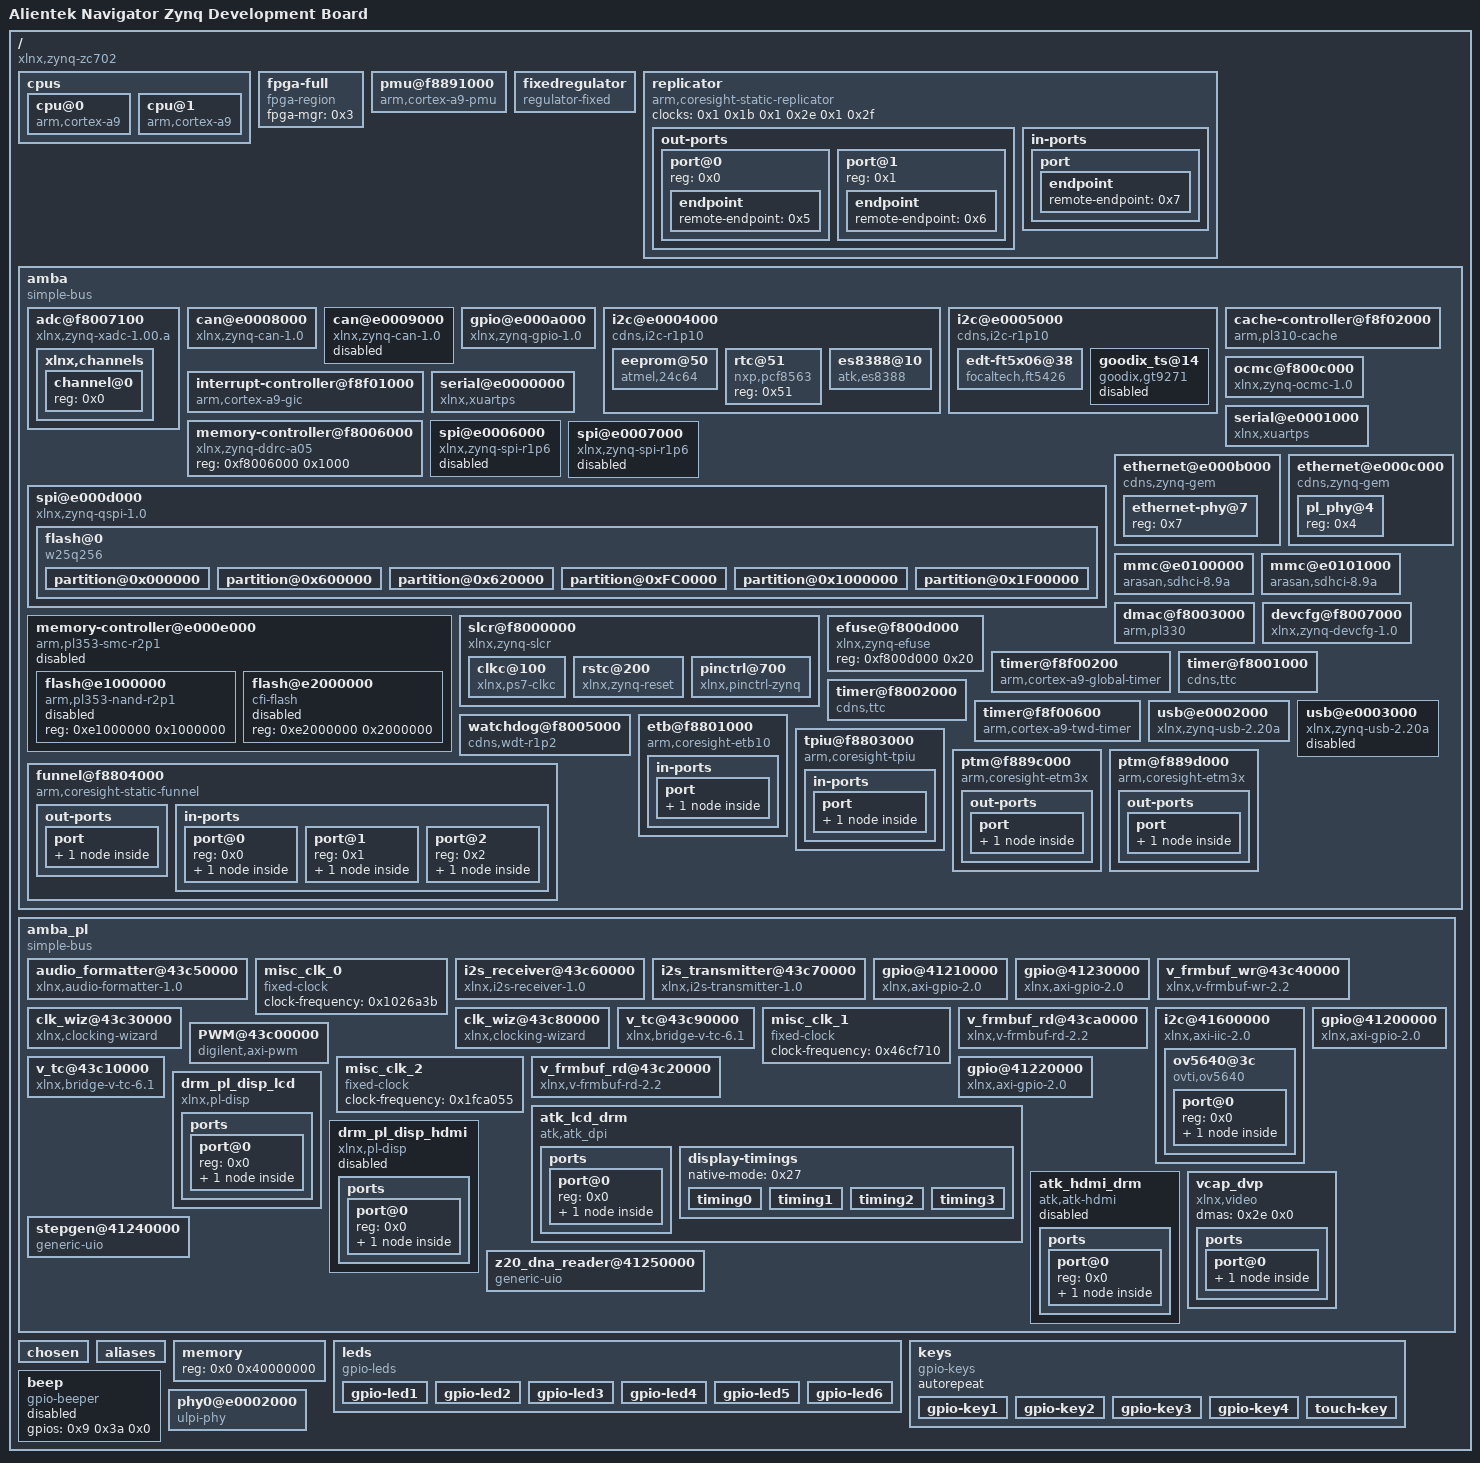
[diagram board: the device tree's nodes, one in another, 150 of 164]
/dts-v1/;

/ {
	#address-cells = <0x1>;
	#size-cells = <0x1>;
	compatible = "xlnx,zynq-zc702", "xlnx,zynq-7000";
	model = "Alientek Navigator Zynq Development Board";

	cpus {
		#address-cells = <0x1>;
		#size-cells = <0x0>;

		cpu@0 {
			compatible = "arm,cortex-a9";
			device_type = "cpu";
			reg = <0x0>;
			clocks = <0x1 0x3>;
			clock-latency = <0x3e8>;
			cpu0-supply = <0x2>;
			operating-points = <0xbb2ca 0xf4240 0x5d965 0xf4240>;
			phandle = <0x13>;
		};

		cpu@1 {
			compatible = "arm,cortex-a9";
			device_type = "cpu";
			reg = <0x1>;
			clocks = <0x1 0x3>;
			phandle = <0x15>;
		};
	};

	fpga-full {
		compatible = "fpga-region";
		fpga-mgr = <0x3>;
		#address-cells = <0x1>;
		#size-cells = <0x1>;
		ranges;
	};

	pmu@f8891000 {
		compatible = "arm,cortex-a9-pmu";
		interrupts = <0x0 0x5 0x4 0x0 0x6 0x4>;
		interrupt-parent = <0x4>;
		reg = <0xf8891000 0x1000 0xf8893000 0x1000>;
	};

	fixedregulator {
		compatible = "regulator-fixed";
		regulator-name = "VCCPINT";
		regulator-min-microvolt = <0xf4240>;
		regulator-max-microvolt = <0xf4240>;
		regulator-boot-on;
		regulator-always-on;
		phandle = <0x2>;
	};

	replicator {
		compatible = "arm,coresight-static-replicator";
		clocks = <0x1 0x1b 0x1 0x2e 0x1 0x2f>;
		clock-names = "apb_pclk", "dbg_trc", "dbg_apb";

		out-ports {
			#address-cells = <0x1>;
			#size-cells = <0x0>;

			port@0 {
				reg = <0x0>;

				endpoint {
					remote-endpoint = <0x5>;
					phandle = <0xf>;
				};
			};

			port@1 {
				reg = <0x1>;

				endpoint {
					remote-endpoint = <0x6>;
					phandle = <0xe>;
				};
			};
		};

		in-ports {

			port {

				endpoint {
					remote-endpoint = <0x7>;
					phandle = <0x10>;
				};
			};
		};
	};

	amba {
		u-boot,dm-pre-reloc;
		compatible = "simple-bus";
		#address-cells = <0x1>;
		#size-cells = <0x1>;
		interrupt-parent = <0x4>;
		ranges;

		adc@f8007100 {
			compatible = "xlnx,zynq-xadc-1.00.a";
			reg = <0xf8007100 0x20>;
			interrupts = <0x0 0x7 0x4>;
			interrupt-parent = <0x4>;
			clocks = <0x1 0xc>;
			status = "okay";

			xlnx,channels {
				#address-cells = <0x1>;
				#size-cells = <0x0>;

				channel@0 {
					reg = <0x0>;
				};
			};
		};

		can@e0008000 {
			compatible = "xlnx,zynq-can-1.0";
			status = "okay";
			clocks = <0x1 0x13 0x1 0x24>;
			clock-names = "can_clk", "pclk";
			reg = <0xe0008000 0x1000>;
			interrupts = <0x0 0x1c 0x4>;
			interrupt-parent = <0x4>;
			tx-fifo-depth = <0x40>;
			rx-fifo-depth = <0x40>;
		};

		can@e0009000 {
			compatible = "xlnx,zynq-can-1.0";
			status = "disabled";
			clocks = <0x1 0x14 0x1 0x25>;
			clock-names = "can_clk", "pclk";
			reg = <0xe0009000 0x1000>;
			interrupts = <0x0 0x33 0x4>;
			interrupt-parent = <0x4>;
			tx-fifo-depth = <0x40>;
			rx-fifo-depth = <0x40>;
		};

		gpio@e000a000 {
			compatible = "xlnx,zynq-gpio-1.0";
			#gpio-cells = <0x2>;
			clocks = <0x1 0x2a>;
			gpio-controller;
			interrupt-controller;
			#interrupt-cells = <0x2>;
			interrupt-parent = <0x4>;
			interrupts = <0x0 0x14 0x4>;
			reg = <0xe000a000 0x1000>;
			emio-gpio-width = <0xb>;
			gpio-mask-high = <0x0>;
			gpio-mask-low = <0x5600>;
			phandle = <0x9>;
		};

		i2c@e0004000 {
			compatible = "cdns,i2c-r1p10";
			status = "okay";
			clocks = <0x1 0x26>;
			interrupt-parent = <0x4>;
			interrupts = <0x0 0x19 0x4>;
			reg = <0xe0004000 0x1000>;
			#address-cells = <0x1>;
			#size-cells = <0x0>;
			clock-frequency = <0x186a0>;

			eeprom@50 {
				compatible = "atmel,24c64";
				reg = <0x50>;
				pagesize = <0x20>;
			};

			rtc@51 {
				compatible = "nxp,pcf8563";
				reg = <0x51>;
			};

			es8388@10 {
				compatible = "atk,es8388";
				reg = <0x10>;
				clock-names = "mclk";
				clocks = <0x8 0x1>;
				#sound-dai-cells = <0x0>;
				status = "okay";
				phandle = <0x1a>;
			};
		};

		i2c@e0005000 {
			compatible = "cdns,i2c-r1p10";
			status = "okay";
			clocks = <0x1 0x27>;
			interrupt-parent = <0x4>;
			interrupts = <0x0 0x30 0x4>;
			reg = <0xe0005000 0x1000>;
			#address-cells = <0x1>;
			#size-cells = <0x0>;
			clock-frequency = <0x186a0>;
			phandle = <0x2c>;

			edt-ft5x06@38 {
				compatible = "focaltech,ft5426", "edt,edt-ft5406";
				status = "okay";
				reg = <0x38>;
				interrupt-parent = <0x9>;
				interrupts = <0x3a 0x2>;
				reset-gpios = <0x9 0x3b 0x1>;
				touchscreen-size-x = <0x400>;
				touchscreen-size-y = <0x258>;
			};

			goodix_ts@14 {
				compatible = "goodix,gt9271", "goodix,gt911", "goodix,gt9xx";
				status = "disabled";
				reg = <0x14>;
				interrupt-parent = <0x9>;
				interrupts = <0x3a 0x0>;
				reset-gpio = <0x9 0x3b 0x1>;
				interrupt-gpio = <0x9 0x3a 0x0>;
				irq-gpios = <0x9 0x3a 0x0>;
				touchscreen-size-x = <0x400>;
				touchscreen-size-y = <0x258>;
			};
		};

		interrupt-controller@f8f01000 {
			compatible = "arm,cortex-a9-gic";
			#interrupt-cells = <0x3>;
			interrupt-controller;
			reg = <0xf8f01000 0x1000 0xf8f00100 0x100>;
			num_cpus = <0x2>;
			num_interrupts = <0x60>;
			phandle = <0x4>;
		};

		cache-controller@f8f02000 {
			compatible = "arm,pl310-cache";
			reg = <0xf8f02000 0x1000>;
			interrupts = <0x0 0x2 0x4>;
			arm,data-latency = <0x3 0x2 0x2>;
			arm,tag-latency = <0x2 0x2 0x2>;
			cache-unified;
			cache-level = <0x2>;
		};

		memory-controller@f8006000 {
			compatible = "xlnx,zynq-ddrc-a05";
			reg = <0xf8006000 0x1000>;
		};

		ocmc@f800c000 {
			compatible = "xlnx,zynq-ocmc-1.0";
			interrupt-parent = <0x4>;
			interrupts = <0x0 0x3 0x4>;
			reg = <0xf800c000 0x1000>;
		};

		serial@e0000000 {
			compatible = "xlnx,xuartps", "cdns,uart-r1p8";
			status = "okay";
			clocks = <0x1 0x17 0x1 0x28>;
			clock-names = "uart_clk", "pclk";
			reg = <0xe0000000 0x1000>;
			interrupts = <0x0 0x1b 0x4>;
			cts-override;
			device_type = "serial";
			port-number = <0x0>;
			u-boot,dm-pre-reloc;
		};

		serial@e0001000 {
			compatible = "xlnx,xuartps", "cdns,uart-r1p8";
			status = "okay";
			clocks = <0x1 0x18 0x1 0x29>;
			clock-names = "uart_clk", "pclk";
			reg = <0xe0001000 0x1000>;
			interrupts = <0x0 0x32 0x4>;
			cts-override;
			device_type = "serial";
			port-number = <0x1>;
		};

		spi@e0006000 {
			compatible = "xlnx,zynq-spi-r1p6";
			reg = <0xe0006000 0x1000>;
			status = "disabled";
			interrupt-parent = <0x4>;
			interrupts = <0x0 0x1a 0x4>;
			clocks = <0x1 0x19 0x1 0x22>;
			clock-names = "ref_clk", "pclk";
			#address-cells = <0x1>;
			#size-cells = <0x0>;
		};

		spi@e0007000 {
			compatible = "xlnx,zynq-spi-r1p6";
			reg = <0xe0007000 0x1000>;
			status = "disabled";
			interrupt-parent = <0x4>;
			interrupts = <0x0 0x31 0x4>;
			clocks = <0x1 0x1a 0x1 0x23>;
			clock-names = "ref_clk", "pclk";
			#address-cells = <0x1>;
			#size-cells = <0x0>;
		};

		spi@e000d000 {
			clock-names = "ref_clk", "pclk";
			clocks = <0x1 0xa 0x1 0x2b>;
			compatible = "xlnx,zynq-qspi-1.0";
			status = "okay";
			interrupt-parent = <0x4>;
			interrupts = <0x0 0x13 0x4>;
			reg = <0xe000d000 0x1000>;
			#address-cells = <0x1>;
			#size-cells = <0x0>;
			is-dual = <0x0>;
			num-cs = <0x1>;
			spi-rx-bus-width = <0x4>;
			spi-tx-bus-width = <0x4>;
			u-boot,dm-pre-reloc;

			flash@0 {
				compatible = "w25q256", "jedec,spi-nor";
				reg = <0x0>;
				spi-max-frequency = <0x2faf080>;
				#address-cells = <0x1>;
				#size-cells = <0x1>;

				partition@0x000000 {
					label = "boot";
					reg = <0x0 0x600000>;
				};

				partition@0x600000 {
					label = "bootenv";
					reg = <0x600000 0x20000>;
				};

				partition@0x620000 {
					label = "reserved";
					reg = <0x620000 0x9a0000>;
					read-only;
				};

				partition@0xFC0000 {
					label = "boot.scr";
					reg = <0xfc0000 0x40000>;
				};

				partition@0x1000000 {
					label = "image.ub";
					reg = <0x1000000 0xf00000>;
				};

				partition@0x1F00000 {
					label = "space";
					reg = <0x1f00000 0x100000>;
				};
			};
		};

		memory-controller@e000e000 {
			#address-cells = <0x1>;
			#size-cells = <0x1>;
			status = "disabled";
			clock-names = "memclk", "apb_pclk";
			clocks = <0x1 0xb 0x1 0x2c>;
			compatible = "arm,pl353-smc-r2p1", "arm,primecell";
			interrupt-parent = <0x4>;
			interrupts = <0x0 0x12 0x4>;
			ranges;
			reg = <0xe000e000 0x1000>;

			flash@e1000000 {
				status = "disabled";
				compatible = "arm,pl353-nand-r2p1";
				reg = <0xe1000000 0x1000000>;
				#address-cells = <0x1>;
				#size-cells = <0x1>;
			};

			flash@e2000000 {
				status = "disabled";
				compatible = "cfi-flash";
				reg = <0xe2000000 0x2000000>;
				#address-cells = <0x1>;
				#size-cells = <0x1>;
			};
		};

		ethernet@e000b000 {
			compatible = "cdns,zynq-gem", "cdns,gem";
			reg = <0xe000b000 0x1000>;
			status = "okay";
			interrupts = <0x0 0x16 0x4>;
			clocks = <0x1 0x1e 0x1 0x1e 0x1 0xd>;
			clock-names = "pclk", "hclk", "tx_clk";
			#address-cells = <0x1>;
			#size-cells = <0x0>;
			phy-mode = "rgmii-id";
			xlnx,ptp-enet-clock = <0x79dbbf3>;
			local-mac-address = [00 0a 35 00 8b 87];
			phy-handle = <0xa>;

			ethernet-phy@7 {
				reg = <0x7>;
				device_type = "ethernet-phy";
				phandle = <0xa>;
			};
		};

		ethernet@e000c000 {
			compatible = "cdns,zynq-gem", "cdns,gem";
			reg = <0xe000c000 0x1000>;
			status = "okay";
			interrupts = <0x0 0x2d 0x4>;
			clocks = <0x1 0x1f 0x1 0x1f 0x1 0xe>;
			clock-names = "pclk", "hclk", "tx_clk";
			#address-cells = <0x1>;
			#size-cells = <0x0>;
			phy-mode = "gmii";
			xlnx,ptp-enet-clock = <0x79dbbf3>;
			local-mac-address = [00 0a 35 00 11 55];
			phy-reset-gpio = <0x9 0x3f 0x1>;
			phy-reset-active-low;
			phy-handle = <0xb>;

			pl_phy@4 {
				reg = <0x4>;
				device_type = "ethernet-phy";
				phandle = <0xb>;
			};
		};

		mmc@e0100000 {
			compatible = "arasan,sdhci-8.9a";
			status = "okay";
			clock-names = "clk_xin", "clk_ahb";
			clocks = <0x1 0x15 0x1 0x20>;
			interrupt-parent = <0x4>;
			interrupts = <0x0 0x18 0x4>;
			reg = <0xe0100000 0x1000>;
			xlnx,has-cd = <0x1>;
			xlnx,has-power = <0x0>;
			xlnx,has-wp = <0x0>;
			u-boot,dm-pre-reloc;
		};

		mmc@e0101000 {
			compatible = "arasan,sdhci-8.9a";
			status = "okay";
			clock-names = "clk_xin", "clk_ahb";
			clocks = <0x1 0x16 0x1 0x21>;
			interrupt-parent = <0x4>;
			interrupts = <0x0 0x2f 0x4>;
			reg = <0xe0101000 0x1000>;
			xlnx,has-cd = <0x0>;
			xlnx,has-power = <0x0>;
			xlnx,has-wp = <0x0>;
		};

		slcr@f8000000 {
			u-boot,dm-pre-reloc;
			#address-cells = <0x1>;
			#size-cells = <0x1>;
			compatible = "xlnx,zynq-slcr", "syscon", "simple-mfd";
			reg = <0xf8000000 0x1000>;
			ranges;
			phandle = <0xc>;

			clkc@100 {
				u-boot,dm-pre-reloc;
				#clock-cells = <0x1>;
				compatible = "xlnx,ps7-clkc";
				fclk-enable = <0xf>;
				clock-output-names = "armpll", "ddrpll", "iopll", "cpu_6or4x", "cpu_3or2x", "cpu_2x", "cpu_1x", "ddr2x", "ddr3x", "dci", "lqspi", "smc", "pcap", "gem0", "gem1", "fclk0", "fclk1", "fclk2", "fclk3", "can0", "can1", "sdio0", "sdio1", "uart0", "uart1", "spi0", "spi1", "dma", "usb0_aper", "usb1_aper", "gem0_aper", "gem1_aper", "sdio0_aper", "sdio1_aper", "spi0_aper", "spi1_aper", "can0_aper", "can1_aper", "i2c0_aper", "i2c1_aper", "uart0_aper", "uart1_aper", "gpio_aper", "lqspi_aper", "smc_aper", "swdt", "dbg_trc", "dbg_apb";
				reg = <0x100 0x100>;
				ps-clk-frequency = <0x1fca055>;
				phandle = <0x1>;
			};

			rstc@200 {
				compatible = "xlnx,zynq-reset";
				reg = <0x200 0x48>;
				#reset-cells = <0x1>;
				syscon = <0xc>;
			};

			pinctrl@700 {
				compatible = "xlnx,pinctrl-zynq";
				reg = <0x700 0x200>;
				syscon = <0xc>;
			};
		};

		dmac@f8003000 {
			compatible = "arm,pl330", "arm,primecell";
			reg = <0xf8003000 0x1000>;
			interrupt-parent = <0x4>;
			interrupt-names = "abort", "dma0", "dma1", "dma2", "dma3", "dma4", "dma5", "dma6", "dma7";
			interrupts = <0x0 0xd 0x4 0x0 0xe 0x4 0x0 0xf 0x4 0x0 0x10 0x4 0x0 0x11 0x4 0x0 0x28 0x4 0x0 0x29 0x4 0x0 0x2a 0x4 0x0 0x2b 0x4>;
			#dma-cells = <0x1>;
			#dma-channels = <0x8>;
			#dma-requests = <0x4>;
			clocks = <0x1 0x1b>;
			clock-names = "apb_pclk";
		};

		devcfg@f8007000 {
			compatible = "xlnx,zynq-devcfg-1.0";
			interrupt-parent = <0x4>;
			interrupts = <0x0 0x8 0x4>;
			reg = <0xf8007000 0x100>;
			clocks = <0x1 0xc 0x1 0xf 0x1 0x10 0x1 0x11 0x1 0x12>;
			clock-names = "ref_clk", "fclk0", "fclk1", "fclk2", "fclk3";
			syscon = <0xc>;
			phandle = <0x3>;
		};

		efuse@f800d000 {
			compatible = "xlnx,zynq-efuse";
			reg = <0xf800d000 0x20>;
		};

		timer@f8f00200 {
			compatible = "arm,cortex-a9-global-timer";
			reg = <0xf8f00200 0x20>;
			interrupts = <0x1 0xb 0x301>;
			interrupt-parent = <0x4>;
			clocks = <0x1 0x4>;
		};

		timer@f8001000 {
			interrupt-parent = <0x4>;
			interrupts = <0x0 0xa 0x4 0x0 0xb 0x4 0x0 0xc 0x4>;
			compatible = "cdns,ttc";
			clocks = <0x1 0x6>;
			reg = <0xf8001000 0x1000>;
		};

		timer@f8002000 {
			interrupt-parent = <0x4>;
			interrupts = <0x0 0x25 0x4 0x0 0x26 0x4 0x0 0x27 0x4>;
			compatible = "cdns,ttc";
			clocks = <0x1 0x6>;
			reg = <0xf8002000 0x1000>;
		};

		timer@f8f00600 {
			interrupt-parent = <0x4>;
			interrupts = <0x1 0xd 0x301>;
			compatible = "arm,cortex-a9-twd-timer";
			reg = <0xf8f00600 0x20>;
			clocks = <0x1 0x4>;
		};

		usb@e0002000 {
			compatible = "xlnx,zynq-usb-2.20a", "chipidea,usb2";
			status = "okay";
			clocks = <0x1 0x1c>;
			interrupt-parent = <0x4>;
			interrupts = <0x0 0x15 0x4>;
			reg = <0xe0002000 0x1000>;
			phy_type = "ulpi";
			usb-reset = <0x9 0x9 0x0>;
			dr_mode = "otg";
			usb-phy = <0xd>;
		};

		usb@e0003000 {
			compatible = "xlnx,zynq-usb-2.20a", "chipidea,usb2";
			status = "disabled";
			clocks = <0x1 0x1d>;
			interrupt-parent = <0x4>;
			interrupts = <0x0 0x2c 0x4>;
			reg = <0xe0003000 0x1000>;
			phy_type = "ulpi";
		};

		watchdog@f8005000 {
			clocks = <0x1 0x2d>;
			compatible = "cdns,wdt-r1p2";
			interrupt-parent = <0x4>;
			interrupts = <0x0 0x9 0x1>;
			reg = <0xf8005000 0x1000>;
			timeout-sec = <0xa>;
			status = "okay";
			reset-on-timeout;
		};

		etb@f8801000 {
			compatible = "arm,coresight-etb10", "arm,primecell";
			reg = <0xf8801000 0x1000>;
			clocks = <0x1 0x1b 0x1 0x2e 0x1 0x2f>;
			clock-names = "apb_pclk", "dbg_trc", "dbg_apb";

			in-ports {

				port {

					endpoint {
						remote-endpoint = <0xe>;
						phandle = <0x6>;
					};
				};
			};
		};

		tpiu@f8803000 {
			compatible = "arm,coresight-tpiu", "arm,primecell";
			reg = <0xf8803000 0x1000>;
			clocks = <0x1 0x1b 0x1 0x2e 0x1 0x2f>;
			clock-names = "apb_pclk", "dbg_trc", "dbg_apb";

			in-ports {

				port {

					endpoint {
						remote-endpoint = <0xf>;
						phandle = <0x5>;
					};
				};
			};
		};

		funnel@f8804000 {
			compatible = "arm,coresight-static-funnel", "arm,primecell";
			reg = <0xf8804000 0x1000>;
			clocks = <0x1 0x1b 0x1 0x2e 0x1 0x2f>;
			clock-names = "apb_pclk", "dbg_trc", "dbg_apb";

			out-ports {

				port {

					endpoint {
						remote-endpoint = <0x10>;
						phandle = <0x7>;
					};
				};
			};

			in-ports {
				#address-cells = <0x1>;
				#size-cells = <0x0>;

				port@0 {
					reg = <0x0>;

					endpoint {
						remote-endpoint = <0x11>;
						phandle = <0x14>;
					};
				};

				port@1 {
					reg = <0x1>;

					endpoint {
						remote-endpoint = <0x12>;
						phandle = <0x16>;
					};
				};

				port@2 {
					reg = <0x2>;

					endpoint {
					};
				};
			};
		};

		ptm@f889c000 {
			compatible = "arm,coresight-etm3x", "arm,primecell";
			reg = <0xf889c000 0x1000>;
			clocks = <0x1 0x1b 0x1 0x2e 0x1 0x2f>;
			clock-names = "apb_pclk", "dbg_trc", "dbg_apb";
			cpu = <0x13>;

			out-ports {

				port {

					endpoint {
						remote-endpoint = <0x14>;
						phandle = <0x11>;
					};
				};
			};
		};

		ptm@f889d000 {
			compatible = "arm,coresight-etm3x", "arm,primecell";
			reg = <0xf889d000 0x1000>;
			clocks = <0x1 0x1b 0x1 0x2e 0x1 0x2f>;
			clock-names = "apb_pclk", "dbg_trc", "dbg_apb";
			cpu = <0x15>;

			out-ports {

				port {

					endpoint {
						remote-endpoint = <0x16>;
						phandle = <0x12>;
					};
				};
			};
		};
	};

	amba_pl {
		#address-cells = <0x1>;
		#size-cells = <0x1>;
		compatible = "simple-bus";
		ranges;

		audio_formatter@43c50000 {
			clock-names = "s_axi_lite_aclk", "m_axis_mm2s_aclk", "aud_mclk", "s_axis_s2mm_aclk";
			clocks = <0x1 0xf 0x1 0xf 0x17 0x1 0xf>;
			compatible = "xlnx,audio-formatter-1.0", "xlnx,audio-formatter-1.0";
			interrupt-names = "irq_mm2s", "irq_s2mm";
			interrupt-parent = <0x4>;
			interrupts = <0x0 0x24 0x4 0x0 0x21 0x4>;
			reg = <0x43c50000 0x10000>;
			xlnx,include-mm2s = <0x1>;
			xlnx,include-s2mm = <0x1>;
			xlnx,max-num-channels-mm2s = <0x2>;
			xlnx,max-num-channels-s2mm = <0x2>;
			xlnx,mm2s-addr-width = <0x20>;
			xlnx,mm2s-async-clock = <0x0>;
			xlnx,mm2s-dataformat = <0x3>;
			xlnx,packing-mode-mm2s = <0x0>;
			xlnx,packing-mode-s2mm = <0x0>;
			xlnx,rx = <0x18>;
			xlnx,s2mm-addr-width = <0x20>;
			xlnx,s2mm-async-clock = <0x0>;
			xlnx,s2mm-dataformat = <0x1>;
			xlnx,tx = <0x19>;
			audio-codec = <0x1a>;
			phandle = <0x1b>;
		};

		misc_clk_0 {
			#clock-cells = <0x0>;
			clock-frequency = <0x1026a3b>;
			compatible = "fixed-clock";
			phandle = <0x17>;
		};

		i2s_receiver@43c60000 {
			aud_mclk = <0x1026a3b>;
			clock-names = "s_axi_ctrl_aclk", "aud_mclk", "m_axis_aud_aclk";
			clocks = <0x1 0xf 0x17 0x1 0xf>;
			compatible = "xlnx,i2s-receiver-1.0", "xlnx,i2s-receiver-1.0";
			interrupt-names = "irq";
			interrupt-parent = <0x4>;
			interrupts = <0x0 0x23 0x4>;
			reg = <0x43c60000 0x10000>;
			xlnx,depth = <0x80>;
			xlnx,dwidth = <0x18>;
			xlnx,num-channels = <0x1>;
			xlnx,snd-pcm = <0x1b>;
			phandle = <0x18>;
		};

		i2s_transmitter@43c70000 {
			aud_mclk = <0x1026a3b>;
			clock-names = "s_axi_ctrl_aclk", "aud_mclk", "s_axis_aud_aclk";
			clocks = <0x1 0xf 0x17 0x1 0xf>;
			compatible = "xlnx,i2s-transmitter-1.0", "xlnx,i2s-transmitter-1.0";
			interrupt-names = "irq";
			interrupt-parent = <0x4>;
			interrupts = <0x0 0x22 0x4>;
			reg = <0x43c70000 0x10000>;
			xlnx,depth = <0x80>;
			xlnx,dwidth = <0x18>;
			xlnx,num-channels = <0x1>;
			xlnx,snd-pcm = <0x1b>;
			phandle = <0x19>;
		};

		gpio@41210000 {
			#gpio-cells = <0x3>;
			clock-names = "s_axi_aclk";
			clocks = <0x1 0xf>;
			compatible = "xlnx,axi-gpio-2.0", "xlnx,xps-gpio-1.00.a";
			gpio-controller;
			reg = <0x41210000 0x10000>;
			xlnx,all-inputs = <0x0>;
			xlnx,all-inputs-2 = <0x0>;
			xlnx,all-outputs = <0x1>;
			xlnx,all-outputs-2 = <0x0>;
			xlnx,dout-default = <0x0>;
			xlnx,dout-default-2 = <0x0>;
			xlnx,gpio-width = <0x2>;
			xlnx,gpio2-width = <0x20>;
			xlnx,interrupt-present = <0x0>;
			xlnx,is-dual = <0x0>;
			xlnx,tri-default = <0xffffffff>;
			xlnx,tri-default-2 = <0xffffffff>;
			phandle = <0x30>;
		};

		gpio@41230000 {
			#gpio-cells = <0x3>;
			clock-names = "s_axi_aclk";
			clocks = <0x1 0xf>;
			compatible = "xlnx,axi-gpio-2.0", "xlnx,xps-gpio-1.00.a";
			gpio-controller;
			reg = <0x41230000 0x10000>;
			xlnx,all-inputs = <0x0>;
			xlnx,all-inputs-2 = <0x0>;
			xlnx,all-outputs = <0x1>;
			xlnx,all-outputs-2 = <0x0>;
			xlnx,dout-default = <0x0>;
			xlnx,dout-default-2 = <0x0>;
			xlnx,gpio-width = <0x1>;
			xlnx,gpio2-width = <0x20>;
			xlnx,interrupt-present = <0x0>;
			xlnx,is-dual = <0x0>;
			xlnx,tri-default = <0xffffffff>;
			xlnx,tri-default-2 = <0xffffffff>;
			phandle = <0x1e>;
		};

		v_frmbuf_wr@43c40000 {
			#dma-cells = <0x1>;
			clock-names = "ap_clk";
			clocks = <0x1 0x10>;
			compatible = "xlnx,v-frmbuf-wr-2.2", "xlnx,axi-frmbuf-wr-v2.1";
			interrupt-names = "interrupt";
			interrupt-parent = <0x4>;
			interrupts = <0x0 0x1f 0x4>;
			reg = <0x43c40000 0x10000>;
			reset-gpios = <0x1c 0x1 0x0 0x1>;
			xlnx,dma-addr-width = <0x20>;
			xlnx,dma-align = <0x8>;
			xlnx,max-height = <0x438>;
			xlnx,max-width = <0x780>;
			xlnx,pixels-per-clock = <0x1>;
			xlnx,s-axi-ctrl-addr-width = <0x7>;
			xlnx,s-axi-ctrl-data-width = <0x20>;
			xlnx,vid-formats = "rgb888", "bgr888";
			xlnx,video-width = <0x8>;
			phandle = <0x2e>;
		};

		clk_wiz@43c30000 {
			#clock-cells = <0x1>;
			clock-names = "s_axi_aclk", "clk_in1";
			clock-output-names = "0x43c30000-lcd_pclk", "0x43c30000-mclk";
			clocks = <0x1 0xf 0x1 0xf>;
			compatible = "xlnx,clocking-wizard";
			reg = <0x43c30000 0x10000>;
			speed-grade = <0x2>;
			xlnx,nr-outputs = <0x2>;
			phandle = <0x8>;
		};

		clk_wiz@43c80000 {
			#clock-cells = <0x1>;
			clock-names = "s_axi_aclk", "clk_in1";
			clock-output-names = "0x43c80000-hdmi_pclk", "0x43c80000-hdmi_pclk_5x";
			clocks = <0x1 0xf 0x1 0xf>;
			compatible = "xlnx,clocking-wizard";
			reg = <0x43c80000 0x10000>;
			speed-grade = <0x2>;
			xlnx,nr-outputs = <0x2>;
			phandle = <0x2b>;
		};

		v_tc@43c90000 {
			clock-names = "clk", "s_axi_aclk";
			clocks = <0x1d 0x1 0xf>;
			compatible = "xlnx,bridge-v-tc-6.1";
			interrupt-names = "irq";
			interrupt-parent = <0x4>;
			interrupts = <0x0 0x35 0x4>;
			reg = <0x43c90000 0x10000>;
			xlnx,generator;
			xlnx,pixels-per-clock = <0x1>;
			phandle = <0x29>;
		};

		misc_clk_1 {
			#clock-cells = <0x0>;
			clock-frequency = <0x46cf710>;
			compatible = "fixed-clock";
			phandle = <0x1d>;
		};

		v_frmbuf_rd@43ca0000 {
			#dma-cells = <0x1>;
			clock-names = "ap_clk";
			clocks = <0x1d>;
			compatible = "xlnx,v-frmbuf-rd-2.2", "xlnx,axi-frmbuf-rd-v2.1";
			interrupt-names = "interrupt";
			interrupt-parent = <0x4>;
			interrupts = <0x0 0x34 0x4>;
			reg = <0x43ca0000 0x10000>;
			reset-gpios = <0x1c 0x2 0x0 0x1>;
			xlnx,dma-addr-width = <0x20>;
			xlnx,dma-align = <0x8>;
			xlnx,max-height = <0x438>;
			xlnx,max-width = <0x780>;
			xlnx,pixels-per-clock = <0x1>;
			xlnx,s-axi-ctrl-addr-width = <0x7>;
			xlnx,s-axi-ctrl-data-width = <0x20>;
			xlnx,vid-formats = "rgb888", "bgr888";
			xlnx,video-width = <0x8>;
			phandle = <0x28>;
		};

		i2c@41600000 {
			#address-cells = <0x1>;
			#size-cells = <0x0>;
			clock-names = "s_axi_aclk";
			clocks = <0x1 0xf>;
			compatible = "xlnx,axi-iic-2.0", "xlnx,xps-iic-2.00.a";
			interrupt-names = "iic2intc_irpt";
			interrupt-parent = <0x4>;
			interrupts = <0x0 0x20 0x4>;
			reg = <0x41600000 0x10000>;
			clock-frequency = <0x186a0>;

			ov5640@3c {
				compatible = "ovti,ov5640";
				reg = <0x3c>;
				pwdn-gpios = <0x9 0x3d 0x0>;
				reset-gpios = <0x9 0x3e 0x1>;
				iprst-gpios = <0x1e 0x0 0x0 0x1>;
				status = "okay";
				#address-cells = <0x1>;
				#size-cells = <0x0>;

				port@0 {
					reg = <0x0>;

					endpoint {
						remote-endpoint = <0x1f>;
						phandle = <0x2f>;
					};
				};
			};
		};

		gpio@41200000 {
			#gpio-cells = <0x3>;
			clock-names = "s_axi_aclk";
			clocks = <0x1 0xf>;
			compatible = "xlnx,axi-gpio-2.0", "xlnx,xps-gpio-1.00.a";
			gpio-controller;
			reg = <0x41200000 0x10000>;
			xlnx,all-inputs = <0x0>;
			xlnx,all-inputs-2 = <0x0>;
			xlnx,all-outputs = <0x0>;
			xlnx,all-outputs-2 = <0x0>;
			xlnx,dout-default = <0x0>;
			xlnx,dout-default-2 = <0x0>;
			xlnx,gpio-width = <0x3>;
			xlnx,gpio2-width = <0x20>;
			xlnx,interrupt-present = <0x0>;
			xlnx,is-dual = <0x0>;
			xlnx,tri-default = <0xffffffff>;
			xlnx,tri-default-2 = <0xffffffff>;
			phandle = <0x25>;
		};

		PWM@43c00000 {
			clock-names = "pwm";
			clocks = <0x1 0xf>;
			compatible = "digilent,axi-pwm";
			reg = <0x43c00000 0x10000>;
			xlnx,pwm-axi-addr-width = <0x7>;
			xlnx,pwm-axi-data-width = <0x20>;
			#pwm-cells = <0x2>;
			npwm = <0x1>;
			phandle = <0x24>;
		};

		v_tc@43c10000 {
			clock-names = "clk", "s_axi_aclk";
			clocks = <0x20 0x1 0xf>;
			compatible = "xlnx,bridge-v-tc-6.1";
			interrupt-names = "irq";
			interrupt-parent = <0x4>;
			interrupts = <0x0 0x1e 0x4>;
			reg = <0x43c10000 0x10000>;
			xlnx,generator;
			xlnx,pixels-per-clock = <0x1>;
			phandle = <0x22>;
		};

		misc_clk_2 {
			#clock-cells = <0x0>;
			clock-frequency = <0x1fca055>;
			compatible = "fixed-clock";
			phandle = <0x20>;
		};

		v_frmbuf_rd@43c20000 {
			#dma-cells = <0x1>;
			clock-names = "ap_clk";
			clocks = <0x20>;
			compatible = "xlnx,v-frmbuf-rd-2.2", "xlnx,axi-frmbuf-rd-v2.1";
			interrupt-names = "interrupt";
			interrupt-parent = <0x4>;
			interrupts = <0x0 0x1d 0x4>;
			reg = <0x43c20000 0x10000>;
			reset-gpios = <0x1c 0x0 0x0 0x1>;
			xlnx,dma-addr-width = <0x20>;
			xlnx,dma-align = <0x8>;
			xlnx,max-height = <0x438>;
			xlnx,max-width = <0x780>;
			xlnx,pixels-per-clock = <0x1>;
			xlnx,s-axi-ctrl-addr-width = <0x7>;
			xlnx,s-axi-ctrl-data-width = <0x20>;
			xlnx,vid-formats = "rgb888", "bgr888";
			xlnx,video-width = <0x8>;
			phandle = <0x21>;
		};

		gpio@41220000 {
			#gpio-cells = <0x3>;
			clock-names = "s_axi_aclk";
			clocks = <0x1 0xf>;
			compatible = "xlnx,axi-gpio-2.0", "xlnx,xps-gpio-1.00.a";
			gpio-controller;
			reg = <0x41220000 0x10000>;
			xlnx,all-inputs = <0x0>;
			xlnx,all-inputs-2 = <0x0>;
			xlnx,all-outputs = <0x1>;
			xlnx,all-outputs-2 = <0x0>;
			xlnx,dout-default = <0x0>;
			xlnx,dout-default-2 = <0x0>;
			xlnx,gpio-width = <0x3>;
			xlnx,gpio2-width = <0x20>;
			xlnx,interrupt-present = <0x0>;
			xlnx,is-dual = <0x0>;
			xlnx,tri-default = <0xffffffff>;
			xlnx,tri-default-2 = <0xffffffff>;
			phandle = <0x1c>;
		};

		drm_pl_disp_lcd {
			compatible = "xlnx,pl-disp";
			dmas = <0x21 0x0>;
			dma-names = "dma0";
			xlnx,no-vblank-irq;
			xlnx,vformat = "BG24";
			xlnx,bridge = <0x22>;

			ports {
				#address-cells = <0x1>;
				#size-cells = <0x0>;

				port@0 {
					reg = <0x0>;

					endpoint {
						remote-endpoint = <0x23>;
						phandle = <0x26>;
					};
				};
			};
		};

		atk_lcd_drm {
			compatible = "atk,atk_dpi";
			status = "okay";
			clocks = <0x8 0x0>;
			clock-names = "lcd_pclk";
			pwms = <0x24 0x0 0x4c4b40>;
			lcdID = <0x25 0x0 0x0 0x1 0x25 0x1 0x0 0x1 0x25 0x2 0x0 0x1>;

			ports {
				#address-cells = <0x1>;
				#size-cells = <0x0>;

				port@0 {
					reg = <0x0>;

					endpoint {
						remote-endpoint = <0x26>;
						phandle = <0x23>;
					};
				};
			};

			display-timings {
				native-mode = <0x27>;

				timing0 {
					clock-frequency = <0x895440>;
					hactive = <0x1e0>;
					vactive = <0x110>;
					hback-porch = <0x2>;
					hfront-porch = <0x2>;
					hsync-len = <0x29>;
					vback-porch = <0x2>;
					vfront-porch = <0x2>;
					vsync-len = <0xa>;
					hsync-active = <0x0>;
					vsync-active = <0x0>;
					de-active = <0x1>;
				};

				timing1 {
					clock-frequency = <0x1fc9350>;
					hactive = <0x320>;
					vactive = <0x1e0>;
					hback-porch = <0x58>;
					hfront-porch = <0x28>;
					hsync-len = <0x80>;
					vback-porch = <0x21>;
					vfront-porch = <0xa>;
					vsync-len = <0x2>;
					hsync-active = <0x0>;
					vsync-active = <0x0>;
					de-active = <0x1>;
					pixelclk-active = <0x0>;
				};

				timing2 {
					clock-frequency = <0x30d4000>;
					hactive = <0x400>;
					vactive = <0x258>;
					hback-porch = <0x8c>;
					hfront-porch = <0xa0>;
					hsync-len = <0x14>;
					vback-porch = <0x14>;
					vfront-porch = <0xc>;
					vsync-len = <0x3>;
					hsync-active = <0x0>;
					vsync-active = <0x0>;
					de-active = <0x1>;
					pixelclk-active = <0x0>;
					phandle = <0x27>;
				};

				timing3 {
					clock-frequency = <0x43ce660>;
					hactive = <0x500>;
					vactive = <0x320>;
					hback-porch = <0x50>;
					hfront-porch = <0x46>;
					hsync-len = <0xa>;
					vback-porch = <0xa>;
					vfront-porch = <0xa>;
					vsync-len = <0x3>;
					hsync-active = <0x0>;
					vsync-active = <0x0>;
					de-active = <0x1>;
					pixelclk-active = <0x0>;
				};
			};
		};

		drm_pl_disp_hdmi {
			compatible = "xlnx,pl-disp";
			status = "disabled";
			dmas = <0x28 0x0>;
			dma-names = "dma0";
			xlnx,vformat = "BG24";
			xlnx,bridge = <0x29>;

			ports {
				#address-cells = <0x1>;
				#size-cells = <0x0>;

				port@0 {
					reg = <0x0>;

					endpoint {
						remote-endpoint = <0x2a>;
						phandle = <0x2d>;
					};
				};
			};
		};

		atk_hdmi_drm {
			compatible = "atk,atk-hdmi";
			status = "disabled";
			clocks = <0x2b 0x0 0x2b 0x1>;
			clock-names = "hdmi_pclk", "hdmi_pclk_5x";
			clk-num = <0x2>;
			ddc-i2c-bus = <0x2c>;
			hpd-gpios = <0x9 0x40 0x0>;

			ports {
				#address-cells = <0x1>;
				#size-cells = <0x0>;

				port@0 {
					reg = <0x0>;

					endpoint {
						remote-endpoint = <0x2d>;
						phandle = <0x2a>;
					};
				};
			};
		};

		vcap_dvp {
			compatible = "xlnx,video";
			dmas = <0x2e 0x0>;
			dma-names = "port0";
			status = "okay";

			ports {
				#address-cells = <0x1>;
				#size-cells = <0x0>;

				port@0 {
					reg = <0x0>;
					direction = "input";

					endpoint {
						remote-endpoint = <0x2f>;
						phandle = <0x1f>;
					};
				};
			};
		};

		stepgen@41240000 {
			compatible = "generic-uio";
			reg = <0x41240000 0x10000>;
			xlnx,name = "zynq_stepgen";
			status = "okay";
		};

		z20_dna_reader@41250000 {
			compatible = "generic-uio";
			reg = <0x41250000 0x10000>;
			xlnx,name = "z20-dna-reader";
			status = "okay";
		};
	};

	chosen {
		bootargs = "console=ttyPS0,115200 cma=50M earlycon root=/dev/mmcblk0p2 rw rootwait";
		stdout-path = "serial0:115200n8";
	};

	aliases {
		ethernet0 = "/amba/ethernet@e000b000";
		ethernet1 = "/amba/ethernet@e000c000";
		i2c0 = "/amba/i2c@e0004000";
		i2c1 = "/amba/i2c@e0005000";
		i2c2 = "/amba_pl/i2c@41600000";
		serial0 = "/amba/serial@e0000000";
		serial1 = "/amba/serial@e0001000";
		spi0 = "/amba/spi@e000d000";
	};

	memory {
		device_type = "memory";
		reg = <0x0 0x40000000>;
	};

	leds {
		compatible = "gpio-leds";

		gpio-led1 {
			label = "led1";
			gpios = <0x9 0x36 0x0>;
			default-state = "on";
		};

		gpio-led2 {
			label = "led2";
			gpios = <0x9 0x0 0x0>;
			linux,default-trigger = "heartbeat";
		};

		gpio-led3 {
			label = "pl_led0";
			gpios = <0x30 0x0 0x0 0x0>;
			default-state = "on";
		};

		gpio-led4 {
			label = "pl_led1";
			gpios = <0x30 0x1 0x0 0x0>;
			linux,default-trigger = "timer";
		};

		gpio-led5 {
			label = "ps_led0";
			gpios = <0x9 0x7 0x0>;
			default-state = "on";
		};

		gpio-led6 {
			label = "ps_led1";
			gpios = <0x9 0x8 0x0>;
			linux,default-trigger = "timer";
		};
	};

	keys {
		compatible = "gpio-keys";
		autorepeat;

		gpio-key1 {
			label = "pl_key0";
			gpios = <0x9 0x37 0x1>;
			linux,code = <0x69>;
			gpio-key,wakeup;
			autorepeat;
		};

		gpio-key2 {
			label = "pl_key1";
			gpios = <0x9 0x38 0x1>;
			linux,code = <0x6a>;
			gpio-key,wakeup;
			autorepeat;
		};

		gpio-key3 {
			label = "ps_key1";
			gpios = <0x9 0xc 0x1>;
			linux,code = <0x67>;
			gpio-key,wakeup;
			autorepeat;
		};

		gpio-key4 {
			label = "ps_key2";
			gpios = <0x9 0xb 0x1>;
			linux,code = <0x6c>;
			gpio-key,wakeup;
			autorepeat;
		};

		touch-key {
			label = "touch_key";
			gpios = <0x9 0x39 0x0>;
			linux,code = <0x1c>;
			gpio-key,wakeup;
			autorepeat;
		};
	};

	beep {
		compatible = "gpio-beeper";
		status = "disabled";
		gpios = <0x9 0x3a 0x0>;
	};

	phy0@e0002000 {
		compatible = "ulpi-phy";
		#phy-cells = <0x0>;
		reg = <0xe0002000 0x1000>;
		view-port = <0x170>;
		drv-vbus;
		phandle = <0xd>;
	};
};
